# A33M11x register map
Vendor: ABOV Semiconductor Co., Ltd.; File version: 1.0
CPU: CM3 r0p1, little endian, MPU, FPU, VTOR, 4 interrupt priority bits
Registers are 32-bit, read-write, reset 0x0 unless marked. A register's access mark holds for its fields unless they carry their own. Offsets are from the block's base; [hi:lo] are bit positions; {n}, {i} and the like mark numbered series; 'fields as' and 'values as' point back to an identical list.

## SCU — System Control Unit
Base 0x40000000
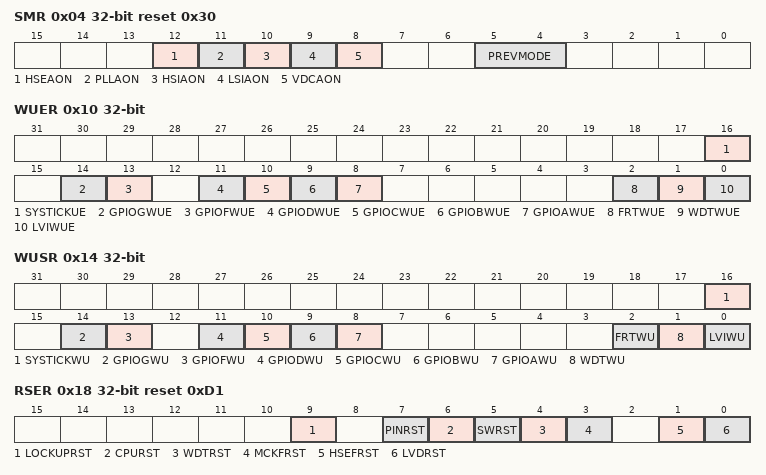
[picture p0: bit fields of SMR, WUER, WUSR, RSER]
0x04 SMR reset 0x30 — System Mode Register
  [12] HSEAON — Auto HSE operation in power down mode
  [11] PLLAON — Auto PLL operation in power down mode
  [10] HSIAON — Auto HSI operation in power down mode
  [9] LSIAON — Auto LSI operation in power down mode
  [8] VDCAON — Auto VDC operation in power down mode
  [5:4] PREVMODE ro — Previous operation mode in current reset event
    0=RUN_MODE (Previous mode is run); 1=SLEEP_MODE (Previous mode is sleep); 2=POWERDOWN_MODE (Previous mode is powerdown); 3=INIT_MODE (Previous mode is init)
0x08 SRCR — System reset control Register
  [0] SWRST wo — Internal soft reset enable bit
0x10 WUER — Wake-up Source Setting Register
  [16] SYSTICKUE — Systick Wake-up source setting
  [14] GPIOGWUE — GPIOG Wake-up source setting
  [13] GPIOFWUE — GPIOF Wake-up source setting
  [11] GPIODWUE — GPIOD Wake-up source setting
  [10] GPIOCWUE — GPIOC Wake-up source setting
  [9] GPIOBWUE — GPIOB Wake-up source setting
  [8] GPIOAWUE — GPIOA Wake-up source setting
  [2] FRTWUE — FRT Wake-up source setting
  [1] WDTWUE — WDT Wake-up source setting
  [0] LVIWUE — LVI Wake-up source setting
0x14 WUSR ro — Wake-up Source Status Register
  [16] SYSTICKWU — Systick Wake-up source status
  [14] GPIOGWU — GPIOG Wake-up source status
  [13] GPIOFWU — GPIOF Wake-up source status
  [11] GPIODWU — GPIOD Wake-up source status
  [10] GPIOCWU — GPIOC Wake-up source status
  [9] GPIOBWU — GPIOB Wake-up source status
  [8] GPIOAWU — GPIOA Wake-up source status
  [2] FRTWU — FRT Wake-up source status
  [1] WDTWU — WDT Wake-up source status
  [0] LVIWU — LVI Wake-up source status
0x18 RSER reset 0xD1 — Reset Source Setting Register
  [9] LOCKUPRST — CPU Lock up reset setting bit
  [7] PINRST — External Pin reset setting bit
  [6] CPURST — CPU request reset setting bit
  [5] SWRST — Software reset setting bit
  [4] WDTRST — WDT reset setting bit
  [3] MCKFRST — MCLK Clock Fail reset setting bit
  [1] HSEFRST — HSE Clock Fail reset setting bit
  [0] LVDRST — LVD reset setting bit
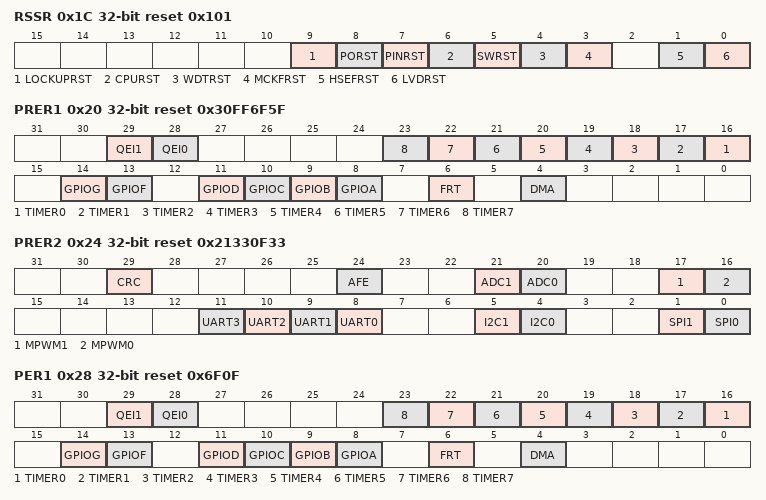
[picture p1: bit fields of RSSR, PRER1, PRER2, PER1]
0x1C RSSR reset 0x101 — Reset Source Status Register
  [9] LOCKUPRST — CPU Lock up reset Status bit
  [8] PORST — POR Status bit
  [7] PINRST — External Pin reset Status bit
  [6] CPURST — CPU request reset Status bit
  [5] SWRST — Software reset Status bit
  [4] WDTRST — WDT reset Status bit
  [3] MCKFRST — MCLK Clock Fail reset Status bit
  [1] HSEFRST — HSE Clock Fail reset Status bit
  [0] LVDRST — LVD reset Status bit
0x20 PRER1 reset 0x30FF6F5F — Peripheral Reset Setting Register1
  [29] QEI1 — QEI1 Reset Mask bit
  [28] QEI0 — QEI0 Reset Mask bit
  [n+16] TIMER{n} (n=0..7) — TIMER{n} Reset Mask bit
  [14] GPIOG — GPIOG Reset Mask bit
  [13] GPIOF — GPIOF Reset Mask bit
  [11] GPIOD — GPIOD Reset Mask bit
  [10] GPIOC — GPIOC Reset Mask bit
  [9] GPIOB — GPIOB Reset Mask bit
  [8] GPIOA — GPIOA Reset Mask bit
  [6] FRT — FRT Reset Mask bit
  [4] DMA — DMA Reset Mask bit
0x24 PRER2 reset 0x21330F33 — Peripheral Reset Setting Register2
  [29] CRC — CRC Reset Mask Bit
  [24] AFE — AFE Reset Mask bit
  [21] ADC1 — ADC1 Reset Mask bit
  [20] ADC0 — ADC0 Reset Mask bit
  [17] MPWM1 — MPWM1 Reset Mask bit
  [16] MPWM0 — MPWM0 Reset Mask bit
  [n+8] UART{n} (n=0..3) — UART{n} Reset Mask bit
  [5] I2C1 — I2C1 Reset Mask bit
  [4] I2C0 — I2C0 Reset Mask bit
  [1] SPI1 — SPI1 Reset Mask bit
  [0] SPI0 — SPI0 Reset Mask bit
0x28 PER1 reset 0x6F0F — Peripheral Enable Register1
  [29] QEI1 — QEI1 Enable bit
  [28] QEI0 — QEI0 Enable bit
  [n+16] TIMER{n} (n=0..7) — TIMER{n} Enable bit
  [14] GPIOG — GPIOG Enable bit
  [13] GPIOF — GPIOF Enable bit
  [11] GPIOD — GPIOD Enable bit
  [10] GPIOC — GPIOC Enable bit
  [9] GPIOB — GPIOB Enable bit
  [8] GPIOA — GPIOA Enable bit
  [6] FRT — FRT Enable bit
  [4] DMA — DMA Enable bit
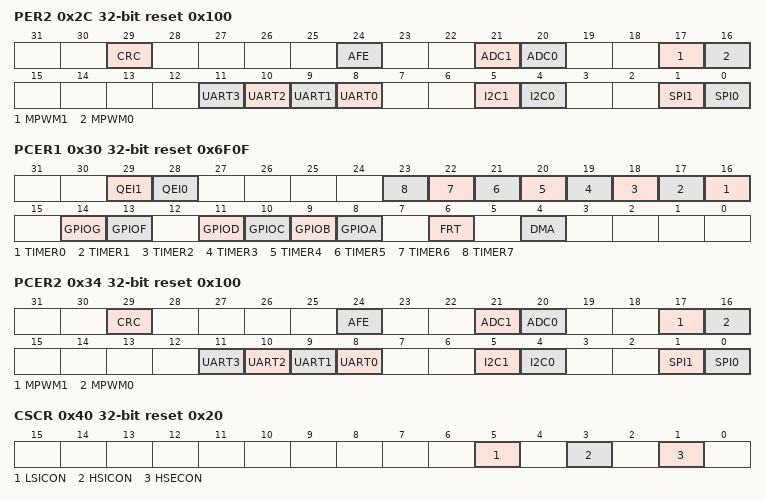
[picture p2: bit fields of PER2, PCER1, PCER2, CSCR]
0x2C PER2 reset 0x100 — Peripheral Enable Register2
  [29] CRC — CRC Enable bit
  [24] AFE — AFE Enable bit
  [21] ADC1 — ADC1 Enable bit
  [20] ADC0 — ADC0 Enable bit
  [17] MPWM1 — MPWM1 Enable bit
  [16] MPWM0 — MPWM0 Enable bit
  [n+8] UART{n} (n=0..3) — UART{n} Enable bit
  [5] I2C1 — I2C1 Enable bit
  [4] I2C0 — I2C0 Enable bit
  [1] SPI1 — SPI1 Enable bit
  [0] SPI0 — SPI0 Enable bit
0x30 PCER1 reset 0x6F0F — Peripheral Clock Enable Register1
  [29] QEI1 — QEI1 Clock Enable bit
  [28] QEI0 — QEI0 Clock Enable bit
  [n+16] TIMER{n} (n=0..7) — TIMER{n} Clock Enable bit
  [14] GPIOG — GPIOG Clock Enable bit
  [13] GPIOF — GPIOF Clock Enable bit
  [11] GPIOD — GPIOD Clock Enable bit
  [10] GPIOC — GPIOC Clock Enable bit
  [9] GPIOB — GPIOB Clock Enable bit
  [8] GPIOA — GPIOA Clock Enable bit
  [6] FRT — FRT Clock Enable bit
  [4] DMA — DMA Clock Enable bit
0x34 PCER2 reset 0x100 — Peripheral Clock Enable Register2
  [29] CRC — CRC Clock Enable bit
  [24] AFE — AFE Clock Enable bit
  [21] ADC1 — ADC1 Clock Enable bit
  [20] ADC0 — ADC0 Clock Enable bit
  [17] MPWM1 — MPWM1 Clock Enable bit
  [16] MPWM0 — MPWM0 Clock Enable bit
  [n+8] UART{n} (n=0..3) — UART{n} Clock Enable bit
  [5] I2C1 — I2C1 Clock Enable bit
  [4] I2C0 — I2C0 Clock Enable bit
  [1] SPI1 — SPI1 Clock Enable bit
  [0] SPI0 — SPI0 Clock Enable bit
0x40 CSCR reset 0x20 — Clock Source Control Register
  [5] LSICON — Low Speed Internal Oscillator Control bit
  [3] HSICON — High Speed Internal Oscillator Control bit
  [1] HSECON — High Speed External Main Crystal Control bit
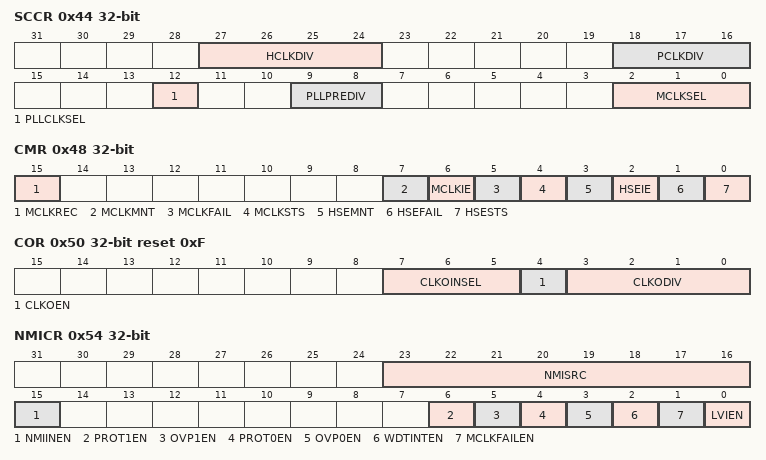
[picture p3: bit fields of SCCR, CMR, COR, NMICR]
0x44 SCCR — System clock control register
  [27:24] HCLKDIV — HCLK input clock divide bit
    9=MCLK_DIV_BY_512 (HCLK=MCLK_div_512); 8=MCLK_DIV_BY_256 (HCLK=MCLK_div_256); 7=MCLK_DIV_BY_128 (HCLK=MCLK_div_128); 6=MCLK_DIV_BY_64 (HCLK=MCLK_div_64); 5=MCLK_DIV_BY_32 (HCLK=MCLK_div_32); 4=MCLK_DIV_BY_16 (HCLK=MCLK_div_16); 3=MCLK_DIV_BY_8 (HCLK=MCLK_div_8); 2=MCLK_DIV_BY_4 (HCLK=MCLK_div_4); 1=MCLK_DIV_BY_2 (HCLK=MCLK_div_2); 0=MCLK_DIV_BY_1 (HCLK=MCLK_div_1)
  [18:16] PCLKDIV — PCLK input clock divide bit
    4=HCLK_DIV_BY_16 (PCLK=HCLK_div_16); 3=HCLK_DIV_BY_8 (PCLK=HCLK_div_8); 2=HCLK_DIV_BY_4 (PCLK=HCLK_div_4); 1=HCLK_DIV_BY_2 (PCLK=HCLK_div_2); 0=MCLK_DIV_BY_1 (HCLK=MCLK_div_1)
  [12] PLLCLKSEL — PLL Input clock selection bit
  [9:8] PLLPREDIV — PLL Input clock divide bit
    3=PLLCLKSEL_DIV_BY_8 (PLL Input clock div 8); 2=PLLCLKSEL_DIV_BY_4 (PLL Input clock div 4); 1=PLLCLKSEL_DIV_BY_2 (PLL Input clock div 2); 0=PLLCLKSEL_DIV_BY_1 (PLL Input clock div 1)
  [2:0] MCLKSEL — System Clock Selection bit
    7=PLL (system clock is PLL); 6=HSE (system clock is HSE); 2=HSI (system clock is HSI); 0=LSI (system clock is LSI)
0x48 CMR — Clock Monitoring Register
  [15] MCLKREC — Automatic recovery of MCLK errors
  [7] MCLKMNT — MCLK Monitoring Enable bit
  [6] MCLKIE — MCLK Fail Interrupt Enable bit
  [5] MCLKFAIL — MCLK Fail Interrupt Flag bit
  [4] MCLKSTS ro — MCLK Status bit
  [3] HSEMNT — HSE Monitoring Enable bit
  [2] HSEIE — HSE Fail Interrupt Enable bit
  [1] HSEFAIL — HSE Fail Interrupt Flag bit
  [0] HSESTS ro — HSE Status bit
0x50 COR reset 0xF — Clock Output Setting Register
  [7:5] CLKOINSEL — Ouput Clock Selection bit
    7=PLL (Output clock is PLL); 6=HSE (Output clock is HSE); 5=HSI (Output clock is HSI); 4=MCLK (Output clock is MCLK); 0=LSI (Output clock is LSI)
  [4] CLKOEN — Clock Output Enable bit
  [3:0] CLKODIV — Clock Output divide Setting bit
0x54 NMICR — NMI Control Register
  [23:16] NMISRC — NMI Source Selection bits
  [15] NMIINEN — NMI Interrupt Enable bit
  [6] PROT1EN — MPWM1 Protection Interrupt Enable bit for NMI Interrupt
  [5] OVP1EN — MPWM1 Over Voltage Interrupt Enable bit for NMI Interrupt
  [4] PROT0EN — MPWM0 Protection Interrupt Enable bit for NMI Interrupt
  [3] OVP0EN — MPWM0 Over Voltage Interrupt Enable bit for NMI Interrupt
  [2] WDTINTEN — WDT Interrupt Enable bit for NMI Interrupt
  [1] MCLKFAILEN — MCLK Fail Interrupt Enable bit for NMI Interrupt
  [0] LVIEN — LVI Interrupt Enable bit for NMI Interrupt
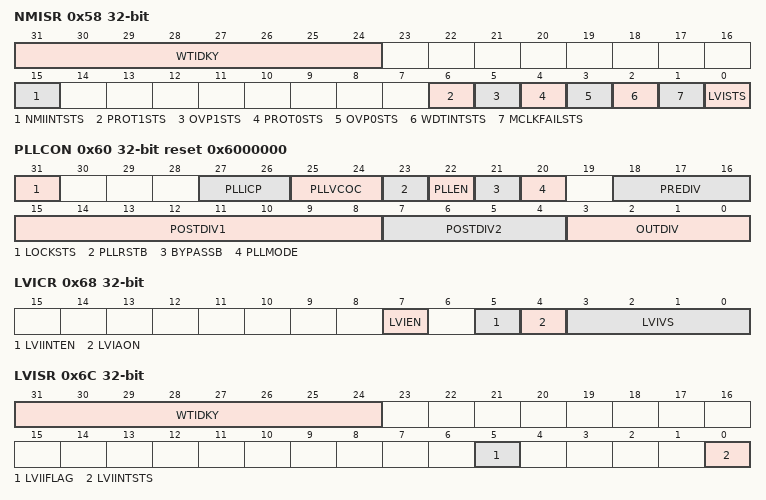
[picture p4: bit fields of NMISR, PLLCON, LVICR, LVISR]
0x58 NMISR — NMI Status Register
  [31:24] WTIDKY wo — NMI Status Register Write Identification Key (0x8C)
  [15] NMIINTSTS ro — NMI Interrupt Status bit(Not Flag)
  [6] PROT1STS — MPWM1 Protection Interrupt Status bit
  [5] OVP1STS — MPWM1 Over Voltage Interrupt Status bit
  [4] PROT0STS — MPWM0 Protection Interrupt Status bit
  [3] OVP0STS — MPWM0 Over Voltage Interrupt Status bit
  [2] WDTINTSTS — WDT Interrupt Status bit
  [1] MCLKFAILSTS — MCLK Fail Interrupt Status bit
  [0] LVISTS — LVI Interrupt Status bit
0x60 PLLCON reset 0x6000000 — PLL Control Register
  [31] LOCKSTS ro — PLL Lock Status Bit
  [27:26] PLLICP — PLL Charge Pump Current Option
    0=5uA (Charge Pump Current); 1=10uA (Charge Pump Current); 2=15uA (Charge Pump Current); 3=20uA (Charge Pump Current)
  [25:24] PLLVCOC — PLL VCO Bias Current Option
    0=1div4 (VCO Bias Current X 1/4); 1=1div2 (VCO Bias Current X 1/2); 2=VCO Bias Current X 1; 3=VCO Bias Current X 2
  [23] PLLRSTB — PLL Reset bit
  [22] PLLEN — PLL Enable bit
  [21] BYPASSB — PLL Bypass Bit
  [20] PLLMODE — PLL VCO Mode Selection bit
  [18:16] PREDIV — FIN Predivider bit
  [15:8] POSTDIV1 — PLL Feedback control 1(N1) bit
  [7:4] POSTDIV2 — PLL Feedback control 2(N2) bit
  [3:0] OUTDIV — Output divider Control(P) bit
0x64 VDCCON reset 0x7F — VDC Control Register
  [7:0] VDCWDLY — VDC Warm-up Delay Count Value Bit
0x68 LVICR — Low Voltage Indicator Control Register
  [7] LVIEN — LVI Enable Bit
  [5] LVIINTEN — LVI Interrupt Enable Bit
  [4] LVIAON — LVI Operation Control Bit in Deep Sleep Mode
  [3:0] LVIVS — LVI Voltage Selection Bit
    0=1.60V; 1=1.69V; 2=1.78V; 3=1.90V; 4=1.99V; 5=2.12V; 6=2.30V; 7=2.47V; 8=2.67V; 9=3.04V; 10=3.18V; 11=3.59V; 12=3.72V; 13=4.03V; 14=4.20V; 15=4.48V
0x6C LVISR — Low Voltage Indicator Status Register
  [31:24] WTIDKY wo — LVI Status Write Identification Key (0x7A)
  [5] LVIIFLAG — LVI Interrupt Flag Bit
  [0] LVIINTSTS ro — LVI Interrupt Status Bit
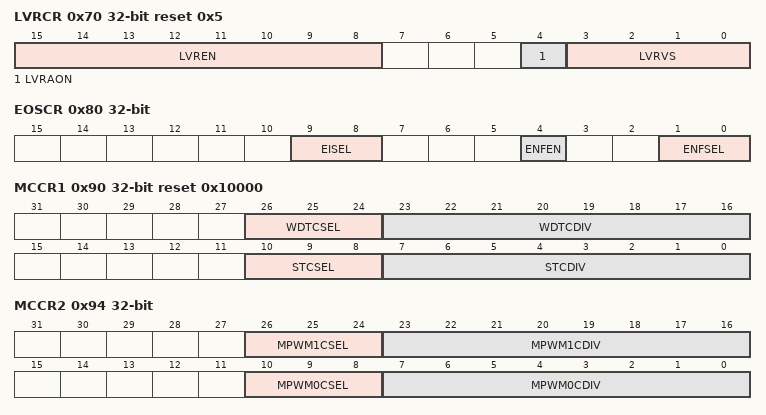
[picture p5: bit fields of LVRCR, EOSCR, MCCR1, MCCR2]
0x70 LVRCR reset 0x5 — Low Voltage Reset Control Register
  [15:8] LVREN — LVR Enable Bit
    0=DISABLE (Disable LVR); 170=ENABLE (Enable LVR)
  [4] LVRAON — LVR Enable Bit
  [3:0] LVRVS — LVR Voltage Selection Bit
    values as LVICR.LVIVS
0x80 EOSCR — External Oscillator Control Register
  [9:8] EISEL — EOSC Current Capability Selection
  [4] ENFEN — EOSC Noise Filter Enable Bit
  [1:0] ENFSEL — EOSC Noise Filter Selection
0x90 MCCR1 reset 0x10000 — MISC Clock Control Register1
  [26:24] WDTCSEL — WDT Clock Source Selection Bit
    7=PLL (Clock Source is PLL); 6=HSE (Clock Source is HSE); 5=HSI (Clock Source is HSI); 4=MCLK (Clock Source is MCLK); 0=LSI (Clock Source is LSI)
  [23:16] WDTCDIV — WDT Clock N divider
  [10:8] STCSEL — SYSTIC Clock Source Selection Bit
    values as WDTCSEL
  [7:0] STCDIV — SYSTIC Clock N divider
0x94 MCCR2 — MISC Clock Control Register2
  [26:24] MPWM1CSEL — MPWM1 Clock Source Selection Bit
    values as MCCR1.WDTCSEL
  [23:16] MPWM1CDIV — MPWM1 Clock N divider
  [10:8] MPWM0CSEL — MPWM0 Clock Source Selection Bit
    values as MCCR1.WDTCSEL
  [7:0] MPWM0CDIV — MPWM0 Clock N divider
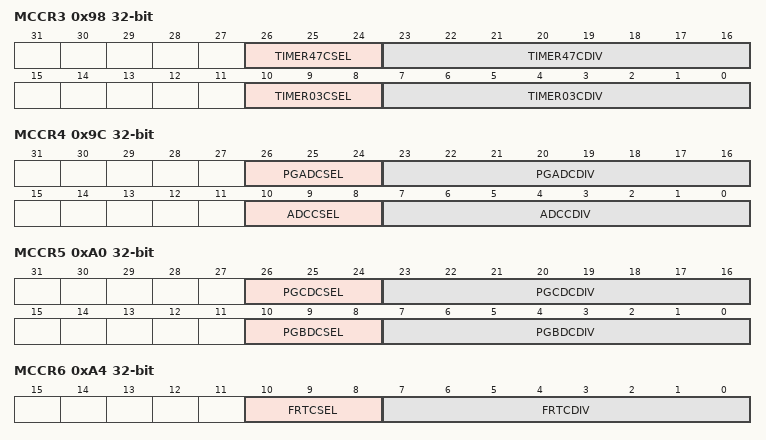
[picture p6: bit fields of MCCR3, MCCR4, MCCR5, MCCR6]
0x98 MCCR3 — MISC Clock Control Register3
  [26:24] TIMER47CSEL — TIMER4/5/6/7 Clock Source Selection Bit
    values as MCCR1.WDTCSEL
  [23:16] TIMER47CDIV — TIMER4/5/6/7 Clock N divider
  [10:8] TIMER03CSEL — TIMER0/1/2/3 Clock Source Selection Bit
    values as MCCR1.WDTCSEL
  [7:0] TIMER03CDIV — TIMER0/1/2/3 Clock N divider
0x9C MCCR4 — MISC Clock Control Register4
  [26:24] PGADCSEL — Port A-B Debounce Clock Source Selection Bit
    values as MCCR1.WDTCSEL
  [23:16] PGADCDIV — Port A-B debounce Clock N divider
  [10:8] ADCCSEL — ADC Clock Source Selection Bit
    values as MCCR1.WDTCSEL
  [7:0] ADCCDIV — ADC Clock N divider
0xA0 MCCR5 — MISC Clock Control Register5
  [26:24] PGCDCSEL — Port F-G Debounce Clock Source Selection Bit
    values as MCCR1.WDTCSEL
  [23:16] PGCDCDIV — Port F-G debounce Clock N divider
  [10:8] PGBDCSEL — Port C-D debounce Clock Source Selection Bit
    values as MCCR1.WDTCSEL
  [7:0] PGBDCDIV — Port C-D debounce Clock N divider
0xA4 MCCR6 — MISC Clock Control Register6
  [10:8] FRTCSEL — FRT Clock Source Selection Bit
    values as MCCR1.WDTCSEL
  [7:0] FRTCDIV — FRT Clock N divider
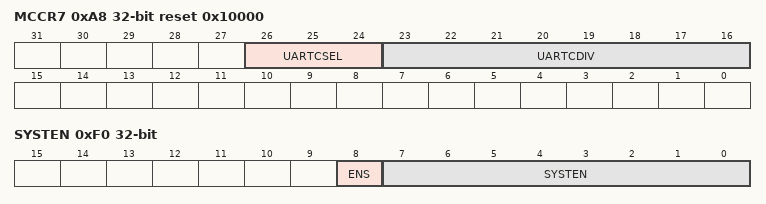
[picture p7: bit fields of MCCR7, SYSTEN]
0xA8 MCCR7 reset 0x10000 — MISC Clock Control Register7
  [26:24] UARTCSEL — UART Clock Source Selection Bit
    values as MCCR1.WDTCSEL
  [23:16] UARTCDIV — UART Clock N divider
0xF0 SYSTEN — System Access Key Register
  [8] ENS ro — Enable Status Bit
  [7:0] SYSTEN wo — System Enable bit

## Notices in the file
Copyright (C) 2012-2014 ARM Limited. All rights reserved.
Purpose: System Viewer Description (SVD) Example (Schema Version 1.1)
This is a description of a none-existent and incomplete device
for demonstration purposes only.
Redistribution and use in source and binary forms, with or without
modification, are permitted provided that the following conditions are met:
- Redistributions of source code must retain the above copyright
notice, this list of conditions and the following disclaimer.
- Redistributions in binary form must reproduce the above copyright
notice, this list of conditions and the following disclaimer in the
documentation and/or other materials provided with the distribution.
- Neither the name of ARM nor the names of its contributors may be used
to endorse or promote products derived from this software without
specific prior written permission.
THIS SOFTWARE IS PROVIDED BY THE COPYRIGHT HOLDERS AND CONTRIBUTORS "AS IS"
AND ANY EXPRESS OR IMPLIED WARRANTIES, INCLUDING, BUT NOT LIMITED TO, THE
IMPLIED WARRANTIES OF MERCHANTABILITY AND FITNESS FOR A PARTICULAR PURPOSE
ARE DISCLAIMED. IN NO EVENT SHALL COPYRIGHT HOLDERS AND CONTRIBUTORS BE
LIABLE FOR ANY DIRECT, INDIRECT, INCIDENTAL, SPECIAL, EXEMPLARY, OR
CONSEQUENTIAL DAMAGES (INCLUDING, BUT NOT LIMITED TO, PROCUREMENT OF
SUBSTITUTE GOODS OR SERVICES; LOSS OF USE, DATA, OR PROFITS; OR BUSINESS
INTERRUPTION) HOWEVER CAUSED AND ON ANY THEORY OF LIABILITY, WHETHER IN
CONTRACT, STRICT LIABILITY, OR TORT (INCLUDING NEGLIGENCE OR OTHERWISE)
ARISING IN ANY WAY OUT OF THE USE OF THIS SOFTWARE, EVEN IF ADVISED OF THE
POSSIBILITY OF SUCH DAMAGE.
